# MU3E_MAX10_PROG_AVMM register map
Vendor: Mu3e; Series: MU3E_FPGA_IP; File version: 0.2.0
CMSIS-SVD description of the max10_prog_avmm control aperture. BaseAddress is 0 because this file describes the relative CSR aperture of the IP; system integration supplies the live slave base address.
Registers are 32-bit, read-write, reset 0x0 unless marked. A register's access mark holds for its fields unless they carry their own. Offsets are from the block's base; lines under a group give offsets from that group; [hi:lo] are bit positions; {n}, {i} and the like mark numbered series; 'fields as' and 'values as' point back to an identical list; <NAME> marks a mode.

## Memory map
0x00000000 MAX10_PROG_AVMM_CSR size 0x1000 — Relative CSR aperture for standard-AVMM MAX10 page programming. The sparse gaps between LAST_ERROR and PAGE_DATA are reserved.

## MAX10_PROG_AVMM_CSR — Relative CSR aperture for standard-AVMM MAX10 page programming. The sparse gaps between LAST_ERROR and PAGE_DATA are reserved.
Base 0x00000000
0x00 ID ro reset 0x4D313050 — IP identifier magic. Default Rev-A value is ASCII "M10P".
  [31:0] value — Packed ASCII identifier.
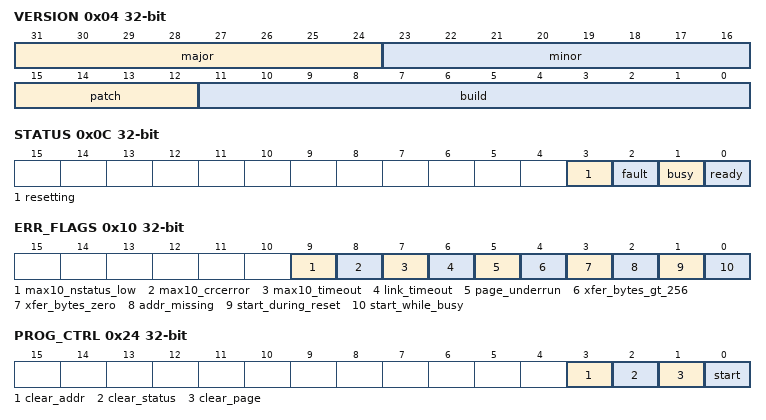
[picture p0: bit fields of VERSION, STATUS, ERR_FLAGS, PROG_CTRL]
0x04 VERSION ro — Packed interface version: [31:24]=major, [23:16]=minor, [15:12]=patch, [11:0]=build.
  [31:24] major — Major version.
  [23:16] minor — Minor version.
  [15:12] patch — Patch version.
  [11:0] build — Build provenance; not part of the software ABI.
0x08 CTRL — Common management control.
  [0] sw_reset write-1-sets — Soft reset pulse.
0x0C STATUS ro — Common ready/busy/fault/resetting summary.
  [3] resetting — Software reset is in progress.
  [2] fault — Sticky summary: ERR_FLAGS != 0.
  [1] busy — At least one local programming operation is in flight.
  [0] ready — IP is CSR-accessible and not held in software reset.
0x10 ERR_FLAGS — Sticky local error flags.
  [9] max10_nstatus_low write-1-clears — MAX10 reported NSTATUS low.
  [8] max10_crcerror write-1-clears — MAX10 reported CRC error.
  [7] max10_timeout write-1-clears — MAX10 reported timeout.
  [6] link_timeout write-1-clears — Downstream Arria/MAX10 link timed out.
  [5] page_underrun write-1-clears — Not enough contiguous page data was staged.
  [4] xfer_bytes_gt_256 write-1-clears — XFER_BYTES exceeded 256 at START time.
  [3] xfer_bytes_zero write-1-clears — XFER_BYTES was zero at START time.
  [2] addr_missing write-1-clears — START requested before FLASH_ADDR was valid.
  [1] start_during_reset write-1-clears — START requested during software reset.
  [0] start_while_busy write-1-clears — START requested while busy.
0x14 ERR_COUNT ro — Saturating count of newly-detected error events.
  [31:0] value — Error event count.
0x18 SCRATCH — Diagnostic scratch register with no side effects.
  [31:0] value — Scratch value.
0x1C FLASH_ADDR — Absolute SPI flash byte address for the next page launch.
  [23:0] flash_addr — Absolute flash byte address.
0x20 XFER_BYTES reset 0x100 — Number of valid payload bytes for the next START request. Reset default is 256.
  [8:0] xfer_bytes — Valid payload byte count, legal range 1..256.
0x24 PROG_CTRL wo — Write-one pulse programming commands. Reads are not meaningful and should be avoided.
  [3] clear_addr — Clear the local address-valid latch and zero FLASH_ADDR.
  [2] clear_status — Clear LAST_ERROR and sticky programming status.
  [1] clear_page — Clear the page aperture and staged-word count.
  [0] start — Launch one programming transaction.
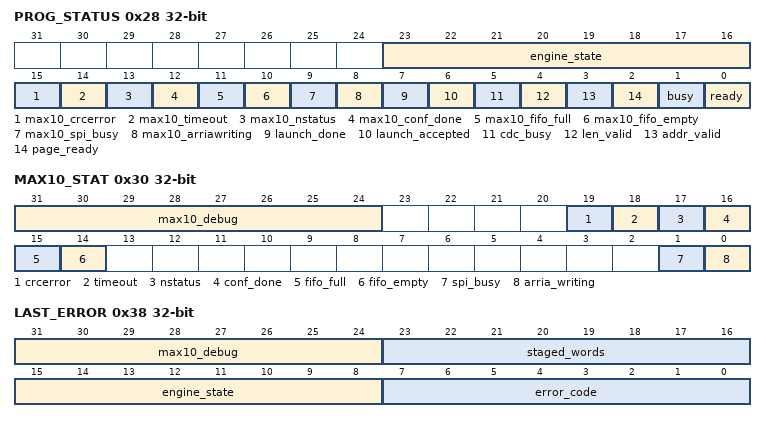
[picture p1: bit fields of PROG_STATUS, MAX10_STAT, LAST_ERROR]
0x28 PROG_STATUS ro — Programming engine status and mirrored MAX10 status summary.
  [23:16] engine_state — Implementation-defined local debug state.
  [15] max10_crcerror — Raw mirror of MAX10 PROGRAMMING_STATUS[19].
  [14] max10_timeout — Raw mirror of MAX10 PROGRAMMING_STATUS[18].
  [13] max10_nstatus — Raw mirror of MAX10 PROGRAMMING_STATUS[17].
  [12] max10_conf_done — Raw mirror of MAX10 PROGRAMMING_STATUS[16].
  [11] max10_fifo_full — Raw mirror of MAX10 PROGRAMMING_STATUS[15].
  [10] max10_fifo_empty — Raw mirror of MAX10 PROGRAMMING_STATUS[14].
  [9] max10_spi_busy — Raw mirror of MAX10 PROGRAMMING_STATUS[1].
  [8] max10_arriawriting — Raw mirror of MAX10 PROGRAMMING_STATUS[0].
  [7] launch_done — Sticky until clear_status; most recent accepted START finished.
  [6] launch_accepted — Sticky until clear_status; most recent START was accepted.
  [5] cdc_busy — Metadata or payload handoff across domains is in progress.
  [4] len_valid — XFER_BYTES is in the legal range 1..256.
  [3] addr_valid — FLASH_ADDR has been written since reset or clear.
  [2] page_ready — Enough contiguous page data is staged for the current XFER_BYTES.
  [1] busy — Programming launch is in progress.
  [0] ready — Local engine is idle and launch-eligible.
0x2C STAGED_WORDS ro — Number of contiguous valid words staged from PAGE_DATA[0].
  [6:0] value — Count of contiguous valid words.
0x30 MAX10_STAT ro — Raw mirror of MAX10 PROGRAMMING_STATUS.
  [31:24] max10_debug — MAX10 FPP debug byte.
  [19] crcerror — CRC error sticky flag.
  [18] timeout — Timeout sticky flag.
  [17] nstatus — NSTATUS state.
  [16] conf_done — CONF_DONE state.
  [15] fifo_full — Programming FIFO full.
  [14] fifo_empty — Programming FIFO empty.
  [1] spi_busy — SPI flash engine busy.
  [0] arria_writing — Arria writing in progress.
0x34 MAX10_COUNT ro — Raw mirror of MAX10 PROGRAMMING_COUNT. Debug only.
  [31:0] value — Raw MAX10 count/debug word.
0x38 LAST_ERROR ro — Last error code and debug snapshot.
  [31:24] max10_debug — MAX10 debug byte captured at failure.
  [23:16] staged_words — Staged word count captured at failure.
  [15:8] engine_state — Local engine state captured at failure.
  [7:0] error_code — Last error code.
{0x80+4i} PAGE_DATA_{i:02} (i=0..63) — Page staging word {i}. Byte lane mapping is little-endian: [7:0]=byte 4n+0 through [31:24]=byte 4n+3.
  [31:0] value — Raw staged page word {i}.
